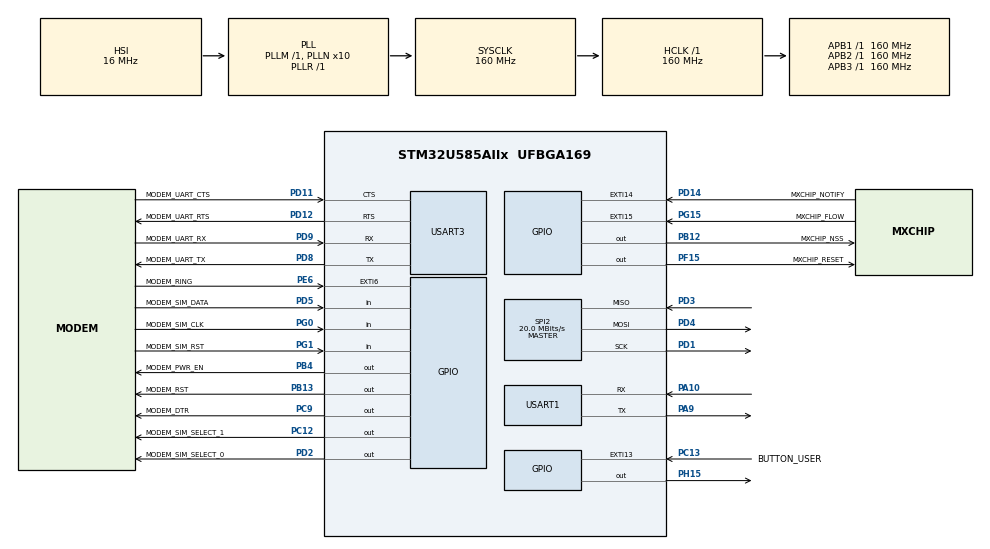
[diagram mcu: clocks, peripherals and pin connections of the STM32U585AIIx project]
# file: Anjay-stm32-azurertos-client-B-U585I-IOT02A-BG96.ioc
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CORTEX_M33_NS.userName=CORTEX_M33
GPDMA1.DESTINC_GPDMACH0=DMA_DINC_INCREMENTED
GPDMA1.DESTINC_GPDMACH4=DMA_DINC_INCREMENTED
GPDMA1.DESTINC_GPDMACH5=DMA_DINC_FIXED
GPDMA1.DIRECTION_GPDMACH5=DMA_MEMORY_TO_PERIPH
GPDMA1.IPHANDLE_GPDMACH0-SIMPLEREQUEST_GPDMACH0=__NULL
GPDMA1.IPHANDLE_GPDMACH4-SIMPLEREQUEST_GPDMACH4=__NULL
GPDMA1.IPHANDLE_GPDMACH5-SIMPLEREQUEST_GPDMACH5=__NULL
GPDMA1.PRIORITY_GPDMACH0=DMA_LOW_PRIORITY_HIGH_WEIGHT
GPDMA1.PRIORITY_GPDMACH4=DMA_LOW_PRIORITY_HIGH_WEIGHT
GPDMA1.PRIORITY_GPDMACH5=DMA_LOW_PRIORITY_HIGH_WEIGHT
GPDMA1.REQUEST_GPDMACH0=GPDMA1_REQUEST_USART1_RX
GPDMA1.REQUEST_GPDMACH4=GPDMA1_REQUEST_SPI2_RX
GPDMA1.REQUEST_GPDMACH5=GPDMA1_REQUEST_SPI2_TX
GPDMA1.SRCINC_GPDMACH5=DMA_SINC_INCREMENTED
GPDMA1.TRANSFERALLOCATEDPORTDEST_GPDMACH4=DMA_DEST_ALLOCATED_PORT1
GPDMA1.TRANSFERALLOCATEDPORTDEST_GPDMACH5=DMA_DEST_ALLOCATED_PORT1
Mcu.Family=STM32U5
Mcu.Name=STM32U585AIIx
Mcu.Package=UFBGA169
Mcu.UserConstants=SAMPLE_MAX_EXPONENTIAL_BACKOFF_IN_SEC,10
NVIC.EXTI13_IRQn=true\:10\:0\:true\:false\:true\:false\:true\:true\:true
NVIC.EXTI14_IRQn=true\:5\:0\:true\:false\:true\:false\:false\:true\:true
NVIC.EXTI15_IRQn=true\:5\:0\:true\:false\:true\:false\:false\:true\:true
NVIC.EXTI6_IRQn=true\:5\:0\:true\:false\:true\:false\:true\:true\:true
NVIC.GPDMA1_Channel0_IRQn=true\:0\:0\:false\:false\:true\:true\:false\:true\:true
NVIC.GPDMA1_Channel4_IRQn=true\:5\:0\:true\:false\:true\:true\:false\:true\:true
NVIC.GPDMA1_Channel5_IRQn=true\:5\:0\:true\:false\:true\:true\:false\:true\:true
NVIC.PriorityGroup=NVIC_PRIORITYGROUP_4
NVIC.SPI2_IRQn=true\:5\:0\:true\:false\:true\:false\:true\:true\:true
NVIC.TIM6_IRQn=true\:15\:0\:false\:false\:true\:false\:false\:true\:true
NVIC.TimeBase=TIM6_IRQn
NVIC.TimeBaseIP=TIM6
NVIC.USART1_IRQn=true\:5\:0\:true\:false\:true\:false\:false\:true\:true
NVIC.USART3_IRQn=true\:5\:0\:true\:false\:true\:false\:true\:true\:true
PA10.Mode=Asynchronous
PA10.Signal=USART1_RX
PA9.Mode=Asynchronous
PA9.Signal=USART1_TX
PB12.GPIO_Label=MXCHIP_NSS
PB12.GPIO_Speed=GPIO_SPEED_FREQ_HIGH
PB12.PinState=GPIO_PIN_SET
PB12.Signal=GPIO_Output
PB13.GPIO_Label=MODEM_RST
PB13.PinState=GPIO_PIN_SET
PB13.Signal=GPIO_Output
PB4\ (NJTRST).GPIO_Label=MODEM_PWR_EN
PB4\ (NJTRST).PinState=GPIO_PIN_SET
PB4\ (NJTRST).Signal=GPIO_Output
PC12.GPIO_Label=MODEM_SIM_SELECT_1
PC12.Signal=GPIO_Output
PC13.GPIO_Label=BUTTON_USER
PC13.Signal=GPXTI13
PC9.GPIO_Label=MODEM_DTR
PC9.Signal=GPIO_Output
PD1.GPIO_Mode=GPIO_MODE_AF_PP
PD1.GPIO_PuPd=GPIO_NOPULL
PD1.GPIO_Speed=GPIO_SPEED_FREQ_LOW
PD1.Mode=Full_Duplex_Master
PD1.Signal=SPI2_SCK
PD11.GPIO_Label=MODEM_UART_CTS
PD11.Mode=CTS_RTS
PD11.Signal=USART3_CTS
PD12.GPIO_Label=MODEM_UART_RTS
PD12.Mode=CTS_RTS
PD12.Signal=USART3_RTS
PD14.GPIO_Label=MXCHIP_NOTIFY
PD14.Signal=GPXTI14
PD2.GPIO_Label=MODEM_SIM_SELECT_0
PD2.Signal=GPIO_Output
PD3.GPIO_Mode=GPIO_MODE_AF_PP
PD3.GPIO_PuPd=GPIO_NOPULL
PD3.GPIO_Speed=GPIO_SPEED_FREQ_LOW
PD3.Mode=Full_Duplex_Master
PD3.Signal=SPI2_MISO
PD4.GPIO_Mode=GPIO_MODE_AF_PP
PD4.GPIO_PuPd=GPIO_NOPULL
PD4.GPIO_Speed=GPIO_SPEED_FREQ_LOW
PD4.Mode=Full_Duplex_Master
PD4.Signal=SPI2_MOSI
PD5.GPIO_Label=MODEM_SIM_DATA
PD5.Signal=GPIO_Input
PD8.GPIO_Label=MODEM_UART_TX
PD8.Mode=Asynchronous
PD8.Signal=USART3_TX
PD9.GPIO_Label=MODEM_UART_RX
PD9.Mode=Asynchronous
PD9.Signal=USART3_RX
PE6.GPIO_Label=MODEM_RING
PE6.Signal=GPXTI6
PF15.GPIO_Label=MXCHIP_RESET
PF15.GPIO_Speed=GPIO_SPEED_FREQ_HIGH
PF15.Signal=GPIO_Output
PG0.GPIO_Label=MODEM_SIM_CLK
PG0.Signal=GPIO_Input
PG1.GPIO_Label=MODEM_SIM_RST
PG1.Signal=GPIO_Input
PG15.GPIO_Label=MXCHIP_FLOW
PG15.Signal=GPXTI15
PH15.PinState=GPIO_PIN_SET
PH15.Signal=GPIO_Output
ProjectManager.HeapSize=0x200
ProjectManager.StackSize=0x400
ProjectManager.TargetToolchain=STM32CubeIDE
RCC.ADCFreq_Value=16000000
RCC.AHBFreq_Value=160000000
RCC.APB1Freq_Value=160000000
RCC.APB1TimFreq_Value=160000000
RCC.APB2Freq_Value=160000000
RCC.APB2TimFreq_Value=160000000
RCC.APB3Freq_Value=160000000
RCC.CortexFreq_Value=160000000
RCC.DACCLockSelectionVirtual=RCC_DAC1CLKSOURCE_LSI
RCC.DACCLockSelectionVirtualString=RCC_DAC1CLKSOURCE_LSI
RCC.EPOD_VALUE=16000000
RCC.HCLKFreq_Value=160000000
RCC.HSE_VALUE=16000000
RCC.HSI48_VALUE=48000000
RCC.HSI_VALUE=16000000
RCC.LSE_VALUE=32768
RCC.LSIDIV_VALUE=32000
RCC.MSIClockRange=RCC_MSIRANGE_0
RCC.MSI_VALUE=48000000
RCC.PLL1R=1
RCC.PLLN=10
RCC.PLLSourceVirtual=RCC_PLLSOURCE_HSI
RCC.SPI2CLockSelection=RCC_SPI2CLKSOURCE_PCLK1
RCC.SYSCLKFreq_VALUE=160000000
RCC.SYSCLKSource=RCC_SYSCLKSOURCE_PLLCLK
RCC.USBFreq_Value=48000000
RCC.VCOOutputFreq_Value=160000000
SPI2.BaudRatePrescaler=SPI_BAUDRATEPRESCALER_8
SPI2.CalculateBaudRate=20.0 MBits/s
SPI2.DataSize=SPI_DATASIZE_8BIT
SPI2.Direction=SPI_DIRECTION_2LINES
SPI2.Mode=SPI_MODE_MASTER
SPI2.NSSPMode=SPI_NSS_PULSE_DISABLE
SPI2.VirtualType=VM_MASTER
THREADX.AZRTOS_APP_MEM_ALLOCATION_METHOD=0
THREADX.TX_APP_MEM_POOL_SIZE=1024
THREADX.TX_MAX_PRIORITIES=64
THREADX.TX_THREAD_USER_EXTENSION=ULONG tx_thread_detached_joinable;
USART1.VirtualMode-Asynchronous=VM_ASYNC
USART3.VirtualMode-Asynchronous=VM_ASYNC
VP_GPDMA1_VS_GPDMACH0.Mode=SIMPLEREQUEST_GPDMACH0
VP_GPDMA1_VS_GPDMACH4.Mode=SIMPLEREQUEST_GPDMACH4
VP_GPDMA1_VS_GPDMACH5.Mode=SIMPLEREQUEST_GPDMACH5
VP_ICACHE_VS_ICACHE.Mode=DirectMappedCache
VP_LPBAMQUEUE_VS_QUEUE.Mode=QUEUEMODE
VP_LPBAM_VS_SIG1.Mode=SmartRun
VP_LPBAM_VS_SIG4.Mode=LPDMA1
VP_PWR_VS_DBSignals.Mode=DisableDeadBatterySignals
VP_PWR_VS_LPOM.Mode=PowerOptimisation
VP_PWR_VS_SECSignals.Mode=Security/Privilege
VP_RNG_VS_RNG.Mode=RNG_Activate
VP_SYS_VS_tim6.Mode=TIM6
VP_THREADX_VS_RTOSJjThreadXJjCoreJjDefault.Mode=Core_Default
board=custom

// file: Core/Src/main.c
/* USER CODE BEGIN Header */
/**
  ******************************************************************************
  * @file           : main.c
  * @brief          : Main program body
  ******************************************************************************
  * @attention
  *
  * Copyright (c) 2023 STMicroelectronics.
  * All rights reserved.
  *
  * This software is licensed under terms that can be found in the LICENSE file
  * in the root directory of this software component.
  * If no LICENSE file comes with this software, it is provided AS-IS.
  *
  ******************************************************************************
  */
/* USER CODE END Header */
#include "main.h"
#include "app_threadx.h"
#include "gpdma.h"
#include "icache.h"
#include "rng.h"
#include "spi.h"
#include "usart.h"
#include "gpio.h"

/* USER CODE BEGIN PV */
UART_HandleTypeDef *const g_console_huart = &huart1;
/* USER CODE END PV */

void SystemClock_Config(void);
static void SystemPower_Config(void);

int main(void)
{

  /* MCU Configuration--------------------------------------------------------*/

  /* Reset of all peripherals, Initializes the Flash interface and the Systick. */
  HAL_Init();

  /* USER CODE BEGIN Init */
#ifndef DEBUG
  HAL_RCC_DeInit();
#endif
  /* USER CODE END Init */

  /* Configure the system clock */
  SystemClock_Config();

  /* Configure the System Power */
  SystemPower_Config();

  /* Initialize all configured peripherals */
  MX_GPIO_Init();
  MX_ICACHE_Init();
  MX_GPDMA1_Init();
  MX_SPI2_Init();
  MX_USART1_UART_Init();
  MX_USART3_UART_Init();
  MX_RNG_Init();

  MX_ThreadX_Init();

  /* We should never get here as control is now taken by the scheduler */
  /* Infinite loop */
  while (1)
  {

  }
}

void SystemClock_Config(void)
{
  RCC_OscInitTypeDef RCC_OscInitStruct = {0};
  RCC_ClkInitTypeDef RCC_ClkInitStruct = {0};

  /** Configure the main internal regulator output voltage
  */
  if (HAL_PWREx_ControlVoltageScaling(PWR_REGULATOR_VOLTAGE_SCALE1) != HAL_OK)
  {
    Error_Handler();
  }

  /** Initializes the CPU, AHB and APB buses clocks
  */
  RCC_OscInitStruct.OscillatorType = RCC_OSCILLATORTYPE_HSI48|RCC_OSCILLATORTYPE_HSI;
  RCC_OscInitStruct.HSIState = RCC_HSI_ON;
  RCC_OscInitStruct.HSI48State = RCC_HSI48_ON;
  RCC_OscInitStruct.HSICalibrationValue = RCC_HSICALIBRATION_DEFAULT;
  RCC_OscInitStruct.PLL.PLLState = RCC_PLL_ON;
  RCC_OscInitStruct.PLL.PLLSource = RCC_PLLSOURCE_HSI;
  RCC_OscInitStruct.PLL.PLLMBOOST = RCC_PLLMBOOST_DIV1;
  RCC_OscInitStruct.PLL.PLLM = 1;
  RCC_OscInitStruct.PLL.PLLN = 10;
  RCC_OscInitStruct.PLL.PLLP = 2;
  RCC_OscInitStruct.PLL.PLLQ = 2;
  RCC_OscInitStruct.PLL.PLLR = 1;
  RCC_OscInitStruct.PLL.PLLRGE = RCC_PLLVCIRANGE_1;
  RCC_OscInitStruct.PLL.PLLFRACN = 0;
  if (HAL_RCC_OscConfig(&RCC_OscInitStruct) != HAL_OK)
  {
    Error_Handler();
  }

  /** Initializes the CPU, AHB and APB buses clocks
  */
  RCC_ClkInitStruct.ClockType = RCC_CLOCKTYPE_HCLK|RCC_CLOCKTYPE_SYSCLK
                              |RCC_CLOCKTYPE_PCLK1|RCC_CLOCKTYPE_PCLK2
                              |RCC_CLOCKTYPE_PCLK3;
  RCC_ClkInitStruct.SYSCLKSource = RCC_SYSCLKSOURCE_PLLCLK;
  RCC_ClkInitStruct.AHBCLKDivider = RCC_SYSCLK_DIV1;
  RCC_ClkInitStruct.APB1CLKDivider = RCC_HCLK_DIV1;
  RCC_ClkInitStruct.APB2CLKDivider = RCC_HCLK_DIV1;
  RCC_ClkInitStruct.APB3CLKDivider = RCC_HCLK_DIV1;

  if (HAL_RCC_ClockConfig(&RCC_ClkInitStruct, FLASH_LATENCY_4) != HAL_OK)
  {
    Error_Handler();
  }
}

/**
  * @brief Power Configuration
  * @retval None
  */
static void SystemPower_Config(void)
{
  HAL_PWREx_EnableVddIO2();

  /*
   * Disable the internal Pull-Up in Dead Battery pins of UCPD peripheral
   */
  HAL_PWREx_DisableUCPDDeadBattery();
}

/* USER CODE BEGIN 4 */
int __io_putchar(int ch) {
  HAL_UART_Transmit(&huart1, (uint8_t *)&ch, 1, 0xFFFF);
  return ch;
}
/* USER CODE END 4 */

void HAL_TIM_PeriodElapsedCallback(TIM_HandleTypeDef *htim)
{
  if (htim->Instance == TIM6) {
    HAL_IncTick();
  }
}

void Error_Handler(void)
{
  __disable_irq();
  while (1)
  {
  }
}
